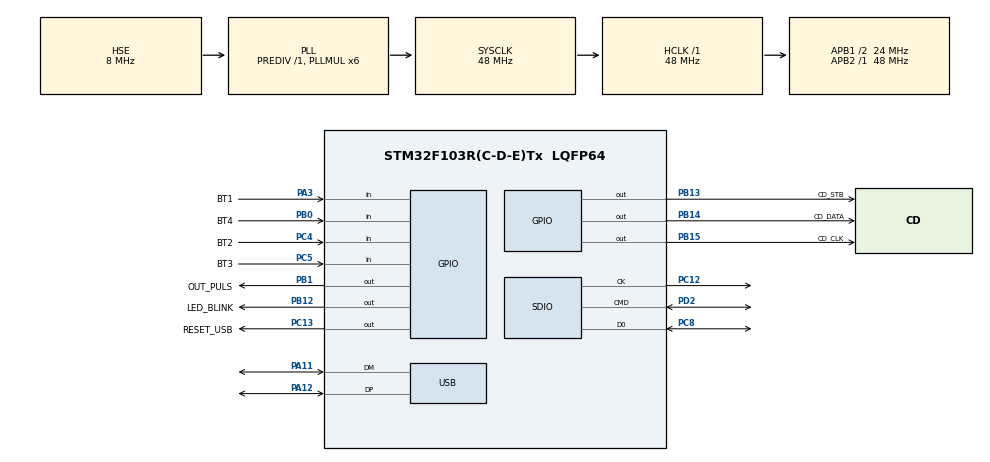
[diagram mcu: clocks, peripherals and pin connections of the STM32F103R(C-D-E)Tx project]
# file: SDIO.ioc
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FATFS._CODE_PAGE=1252
FATFS._USE_STRFUNC=1
Mcu.Family=STM32F1
Mcu.Name=STM32F103R(C-D-E)Tx
Mcu.Package=LQFP64
NVIC.PriorityGroup=NVIC_PRIORITYGROUP_4
NVIC.SDIO_IRQn=true\:0\:0\:false\:false\:true\:true
NVIC.USB_LP_CAN1_RX0_IRQn=true\:0\:0\:false\:false\:true\:false
PA11.Mode=Device
PA11.Signal=USB_DM
PA12.Mode=Device
PA12.Signal=USB_DP
PA3.GPIO_Label=BT1
PA3.GPIO_PuPd=GPIO_PULLUP
PA3.Signal=GPIO_Input
PB0.GPIO_Label=BT4
PB0.GPIO_PuPd=GPIO_PULLUP
PB0.Signal=GPIO_Input
PB1.GPIO_Label=OUT_PULS
PB1.GPIO_Speed=GPIO_SPEED_FREQ_HIGH
PB1.Signal=GPIO_Output
PB12.GPIO_Label=LED_BLINK
PB12.Signal=GPIO_Output
PB13.GPIO_Label=CD_STB
PB13.GPIO_Speed=GPIO_SPEED_FREQ_MEDIUM
PB13.Signal=GPIO_Output
PB14.GPIO_Label=CD_DATA
PB14.GPIO_Speed=GPIO_SPEED_FREQ_MEDIUM
PB14.Signal=GPIO_Output
PB15.GPIO_Label=CD_CLK
PB15.GPIO_Speed=GPIO_SPEED_FREQ_MEDIUM
PB15.Signal=GPIO_Output
PC12.Mode=SD_1_bit
PC12.Signal=SDIO_CK
PC13-TAMPER-RTC.GPIO_Label=RESET_USB
PC13-TAMPER-RTC.Signal=GPIO_Output
PC4.GPIO_Label=BT2
PC4.GPIO_PuPd=GPIO_PULLUP
PC4.Signal=GPIO_Input
PC5.GPIO_Label=BT3
PC5.GPIO_PuPd=GPIO_PULLUP
PC5.Signal=GPIO_Input
PC8.Mode=SD_1_bit
PC8.Signal=SDIO_D0
PD0-OSC_IN.Mode=HSE-External-Oscillator
PD0-OSC_IN.Signal=RCC_OSC_IN
PD1-OSC_OUT.Mode=HSE-External-Oscillator
PD1-OSC_OUT.Signal=RCC_OSC_OUT
PD2.Mode=SD_1_bit
PD2.Signal=SDIO_CMD
ProjectManager.HeapSize=0x200
ProjectManager.StackSize=0x400
ProjectManager.TargetToolchain=MDK-ARM V5
RCC.AHBFreq_Value=48000000
RCC.APB1CLKDivider=RCC_HCLK_DIV2
RCC.APB1Freq_Value=24000000
RCC.APB1TimFreq_Value=48000000
RCC.APB2Freq_Value=48000000
RCC.APB2TimFreq_Value=48000000
RCC.HCLKFreq_Value=48000000
RCC.PLLMUL=RCC_PLL_MUL6
RCC.PLLSourceVirtual=RCC_PLLSOURCE_HSE
RCC.SYSCLKFreq_VALUE=48000000
RCC.SYSCLKSource=RCC_SYSCLKSOURCE_PLLCLK
RCC.USBFreq_Value=48000000
USB_DEVICE.CLASS_NAME_FS=CDC
USB_DEVICE.VirtualMode=Cdc
USB_DEVICE.VirtualModeFS=Cdc_FS
VP_FATFS_VS_SDIO.Mode=SDIO
VP_SYS_VS_ND.Mode=No_Debug
VP_USB_DEVICE_VS_USB_DEVICE_CDC_FS.Mode=CDC_FS
board=SDIO

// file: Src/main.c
/**
  ******************************************************************************
  * File Name          : main.c
  * Description        : Main program body
  ******************************************************************************
  * This notice applies to any and all portions of this file
  * that are not between comment pairs USER CODE BEGIN and
  * USER CODE END. Other portions of this file, whether
  * inserted by the user or by software development tools
  * are owned by their respective copyright owners.
  *
  * Copyright (c) 2018 STMicroelectronics International N.V.
  * All rights reserved.
  *
  * Redistribution and use in source and binary forms, with or without
  * modification, are permitted, provided that the following conditions are met:
  *
  * 1. Redistribution of source code must retain the above copyright notice,
  *    this list of conditions and the following disclaimer.
  * 2. Redistributions in binary form must reproduce the above copyright notice,
  *    this list of conditions and the following disclaimer in the documentation
  *    and/or other materials provided with the distribution.
  * 3. Neither the name of STMicroelectronics nor the names of other
  *    contributors to this software may be used to endorse or promote products
  *    derived from this software without specific written permission.
  * 4. This software, including modifications and/or derivative works of this
  *    software, must execute solely and exclusively on microcontroller or
  *    microprocessor devices manufactured by or for STMicroelectronics.
  * 5. Redistribution and use of this software other than as permitted under
  *    this license is void and will automatically terminate your rights under
  *    this license.
  *
  * THIS SOFTWARE IS PROVIDED BY STMICROELECTRONICS AND CONTRIBUTORS "AS IS"
  * AND ANY EXPRESS, IMPLIED OR STATUTORY WARRANTIES, INCLUDING, BUT NOT
  * LIMITED TO, THE IMPLIED WARRANTIES OF MERCHANTABILITY, FITNESS FOR A
  * PARTICULAR PURPOSE AND NON-INFRINGEMENT OF THIRD PARTY INTELLECTUAL PROPERTY
  * RIGHTS ARE DISCLAIMED TO THE FULLEST EXTENT PERMITTED BY LAW. IN NO EVENT
  * SHALL STMICROELECTRONICS OR CONTRIBUTORS BE LIABLE FOR ANY DIRECT, INDIRECT,
  * INCIDENTAL, SPECIAL, EXEMPLARY, OR CONSEQUENTIAL DAMAGES (INCLUDING, BUT NOT
  * LIMITED TO, PROCUREMENT OF SUBSTITUTE GOODS OR SERVICES; LOSS OF USE, DATA,
  * OR PROFITS; OR BUSINESS INTERRUPTION) HOWEVER CAUSED AND ON ANY THEORY OF
  * LIABILITY, WHETHER IN CONTRACT, STRICT LIABILITY, OR TORT (INCLUDING
  * NEGLIGENCE OR OTHERWISE) ARISING IN ANY WAY OUT OF THE USE OF THIS SOFTWARE,
  * EVEN IF ADVISED OF THE POSSIBILITY OF SUCH DAMAGE.
  *
  ******************************************************************************
  */
#include "main.h"
#include "stm32f1xx_hal.h"
#include "fatfs.h"
#include "usb_device.h"

/* USER CODE BEGIN Includes */
#include "control.h"

/* USER CODE END Includes */

SD_HandleTypeDef hsd;

/* USER CODE BEGIN PV */
/* Private variables ---------------------------------------------------------*/
extern uint8_t Update_USB;

/* USER CODE END PV */

void SystemClock_Config(void);
static void MX_GPIO_Init(void);
static void MX_SDIO_SD_Init(void);

/* USER CODE BEGIN PFP */
/* Private function prototypes -----------------------------------------------*/

/* USER CODE END PFP */

int main(void)
{

  /* MCU Configuration----------------------------------------------------------*/

  /* Reset of all peripherals, Initializes the Flash interface and the Systick. */
  HAL_Init();

  /* Configure the system clock */
  SystemClock_Config();

  /* Initialize all configured peripherals */
  MX_GPIO_Init();
  MX_SDIO_SD_Init();
  MX_FATFS_Init();
  MX_USB_DEVICE_Init();

  /* USER CODE BEGIN 2 */
//   if(BSP_SD_Init() == MSD_OK);
//    {
//        fresult = f_mount(&fatfs,"",1);
//        if(fresult ==FR_OK)
//        {

//            control_main_eff();
//
////            fresult = f_open(&myfile,"eff1.bin",FA_READ);
////            if(fresult == FR_OK)
////            {
////                f_read(&myfile,Buff_data,2000,&br);
////                f_close(&myfile);
////            }
//        }
//    }
    HAL_GPIO_WritePin(RESET_USB_GPIO_Port,RESET_USB_Pin,GPIO_PIN_SET);    /* Disable USB */
    control();

  /* USER CODE END 2 */

  /* Infinite loop */
    while (1)
    {

    }

}

/** System Clock Configuration
*/
void SystemClock_Config(void)
{

  RCC_OscInitTypeDef RCC_OscInitStruct;
  RCC_ClkInitTypeDef RCC_ClkInitStruct;
  RCC_PeriphCLKInitTypeDef PeriphClkInit;

    /**Initializes the CPU, AHB and APB busses clocks
    */
  RCC_OscInitStruct.OscillatorType = RCC_OSCILLATORTYPE_HSE;
  RCC_OscInitStruct.HSEState = RCC_HSE_ON;
  RCC_OscInitStruct.HSEPredivValue = RCC_HSE_PREDIV_DIV1;
  RCC_OscInitStruct.HSIState = RCC_HSI_ON;
  RCC_OscInitStruct.PLL.PLLState = RCC_PLL_ON;
  RCC_OscInitStruct.PLL.PLLSource = RCC_PLLSOURCE_HSE;
  RCC_OscInitStruct.PLL.PLLMUL = RCC_PLL_MUL6;
  if (HAL_RCC_OscConfig(&RCC_OscInitStruct) != HAL_OK)
  {
    _Error_Handler(__FILE__, __LINE__);
  }

    /**Initializes the CPU, AHB and APB busses clocks
    */
  RCC_ClkInitStruct.ClockType = RCC_CLOCKTYPE_HCLK|RCC_CLOCKTYPE_SYSCLK
                              |RCC_CLOCKTYPE_PCLK1|RCC_CLOCKTYPE_PCLK2;
  RCC_ClkInitStruct.SYSCLKSource = RCC_SYSCLKSOURCE_PLLCLK;
  RCC_ClkInitStruct.AHBCLKDivider = RCC_SYSCLK_DIV1;
  RCC_ClkInitStruct.APB1CLKDivider = RCC_HCLK_DIV2;
  RCC_ClkInitStruct.APB2CLKDivider = RCC_HCLK_DIV1;

  if (HAL_RCC_ClockConfig(&RCC_ClkInitStruct, FLASH_LATENCY_1) != HAL_OK)
  {
    _Error_Handler(__FILE__, __LINE__);
  }

  PeriphClkInit.PeriphClockSelection = RCC_PERIPHCLK_USB;
  PeriphClkInit.UsbClockSelection = RCC_USBCLKSOURCE_PLL;
  if (HAL_RCCEx_PeriphCLKConfig(&PeriphClkInit) != HAL_OK)
  {
    _Error_Handler(__FILE__, __LINE__);
  }

    /**Configure the Systick interrupt time
    */
  HAL_SYSTICK_Config(HAL_RCC_GetHCLKFreq()/1000);

    /**Configure the Systick
    */
  HAL_SYSTICK_CLKSourceConfig(SYSTICK_CLKSOURCE_HCLK);

  /* SysTick_IRQn interrupt configuration */
  HAL_NVIC_SetPriority(SysTick_IRQn, 0, 0);
}

/* SDIO init function */
static void MX_SDIO_SD_Init(void)
{

  hsd.Instance = SDIO;
  hsd.Init.ClockEdge = SDIO_CLOCK_EDGE_RISING;
  hsd.Init.ClockBypass = SDIO_CLOCK_BYPASS_DISABLE;
  hsd.Init.ClockPowerSave = SDIO_CLOCK_POWER_SAVE_DISABLE;
  hsd.Init.BusWide = SDIO_BUS_WIDE_1B;
  hsd.Init.HardwareFlowControl = SDIO_HARDWARE_FLOW_CONTROL_DISABLE;
  hsd.Init.ClockDiv = 0;

}

/** Configure pins as
        * Analog
        * Input
        * Output
        * EVENT_OUT
        * EXTI
*/
static void MX_GPIO_Init(void)
{

  GPIO_InitTypeDef GPIO_InitStruct;

  /* GPIO Ports Clock Enable */
  __HAL_RCC_GPIOC_CLK_ENABLE();
  __HAL_RCC_GPIOD_CLK_ENABLE();
  __HAL_RCC_GPIOA_CLK_ENABLE();
  __HAL_RCC_GPIOB_CLK_ENABLE();

  /*Configure GPIO pin Output Level */
  HAL_GPIO_WritePin(RESET_USB_GPIO_Port, RESET_USB_Pin, GPIO_PIN_RESET);

  /*Configure GPIO pin Output Level */
  HAL_GPIO_WritePin(GPIOB, OUT_PULS_Pin|LED_BLINK_Pin|CD_STB_Pin|CD_DATA_Pin
                          |CD_CLK_Pin, GPIO_PIN_RESET);

  /*Configure GPIO pin : RESET_USB_Pin */
  GPIO_InitStruct.Pin = RESET_USB_Pin;
  GPIO_InitStruct.Mode = GPIO_MODE_OUTPUT_PP;
  GPIO_InitStruct.Speed = GPIO_SPEED_FREQ_LOW;
  HAL_GPIO_Init(RESET_USB_GPIO_Port, &GPIO_InitStruct);

  /*Configure GPIO pin : BT1_Pin */
  GPIO_InitStruct.Pin = BT1_Pin;
  GPIO_InitStruct.Mode = GPIO_MODE_INPUT;
  GPIO_InitStruct.Pull = GPIO_PULLUP;
  HAL_GPIO_Init(BT1_GPIO_Port, &GPIO_InitStruct);

  /*Configure GPIO pins : BT2_Pin BT3_Pin */
  GPIO_InitStruct.Pin = BT2_Pin|BT3_Pin;
  GPIO_InitStruct.Mode = GPIO_MODE_INPUT;
  GPIO_InitStruct.Pull = GPIO_PULLUP;
  HAL_GPIO_Init(GPIOC, &GPIO_InitStruct);

  /*Configure GPIO pin : BT4_Pin */
  GPIO_InitStruct.Pin = BT4_Pin;
  GPIO_InitStruct.Mode = GPIO_MODE_INPUT;
  GPIO_InitStruct.Pull = GPIO_PULLUP;
  HAL_GPIO_Init(BT4_GPIO_Port, &GPIO_InitStruct);

  /*Configure GPIO pin : OUT_PULS_Pin */
  GPIO_InitStruct.Pin = OUT_PULS_Pin;
  GPIO_InitStruct.Mode = GPIO_MODE_OUTPUT_PP;
  GPIO_InitStruct.Speed = GPIO_SPEED_FREQ_HIGH;
  HAL_GPIO_Init(OUT_PULS_GPIO_Port, &GPIO_InitStruct);

  /*Configure GPIO pin : LED_BLINK_Pin */
  GPIO_InitStruct.Pin = LED_BLINK_Pin;
  GPIO_InitStruct.Mode = GPIO_MODE_OUTPUT_PP;
  GPIO_InitStruct.Speed = GPIO_SPEED_FREQ_LOW;
  HAL_GPIO_Init(LED_BLINK_GPIO_Port, &GPIO_InitStruct);

  /*Configure GPIO pins : CD_STB_Pin CD_DATA_Pin CD_CLK_Pin */
  GPIO_InitStruct.Pin = CD_STB_Pin|CD_DATA_Pin|CD_CLK_Pin;
  GPIO_InitStruct.Mode = GPIO_MODE_OUTPUT_PP;
  GPIO_InitStruct.Speed = GPIO_SPEED_FREQ_MEDIUM;
  HAL_GPIO_Init(GPIOB, &GPIO_InitStruct);

}

void _Error_Handler(char * file, int line)
{
  while(1)
  {
  }
}

/************************ (C) COPYRIGHT STMicroelectronics *****END OF FILE****/
